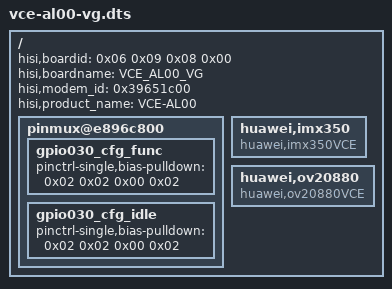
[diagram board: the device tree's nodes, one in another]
/dts-v1/;

/include/ "../variants/vce-al00.dtsi"

/ {
	hisi,boardid = <0x06 0x09 0x08 0x00>;
	hisi,boardname = "VCE_AL00_VG";
	hisi,modem_id = <0x39651c00>;
	hisi,product_name = "VCE-AL00";

	pinmux@e896c800 {
		gpio030_cfg_func {
			pinctrl-single,bias-pulldown = <0x02 0x02 0x00 0x02>;
		};

		gpio030_cfg_idle {
			pinctrl-single,bias-pulldown = <0x02 0x02 0x00 0x02>;
		};
	};

	huawei,imx350 {
		compatible = "huawei,imx350VCE";
		status = "ok";
		phandle = <0x6d1>;
	};

	huawei,ov20880 {
		compatible = "huawei,ov20880VCE";
		status = "ok";
		phandle = <0x6d2>;
	};

	__symbols__ {
		huawei_imx350 = "/huawei,imx350";
		huawei_ov20880 = "/huawei,ov20880";
	};
};
